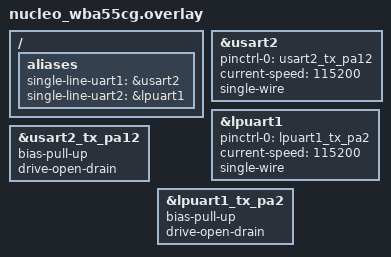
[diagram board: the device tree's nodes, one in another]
/*
 * SPDX-License-Identifier: Apache-2.0
 *
 * Copyright (c) 2025 STMicroelectronics
 */

&usart2 {
	pinctrl-0 = <&usart2_tx_pa12>;
	current-speed = <115200>;
	single-wire;
	status = "okay";
};

&lpuart1 {
	pinctrl-0 = <&lpuart1_tx_pa2>;
	current-speed = <115200>;
	single-wire;
	status = "okay";
};

&usart2_tx_pa12 {
	bias-pull-up;
	drive-open-drain;
};

&lpuart1_tx_pa2 {
	bias-pull-up;
	drive-open-drain;
};

/ {
	aliases {
		single-line-uart1 = &usart2;
		single-line-uart2 = &lpuart1;
	};
};
